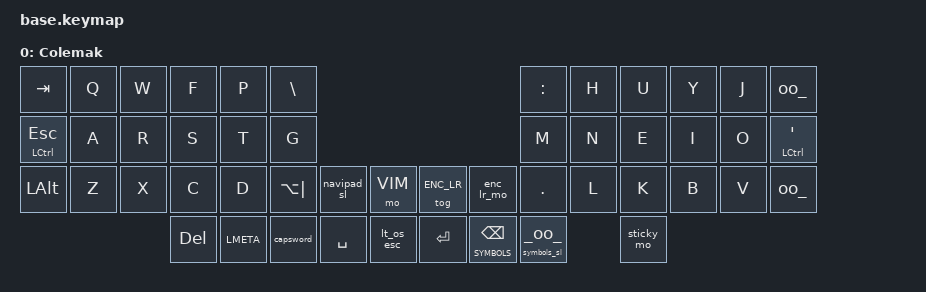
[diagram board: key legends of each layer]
/ {
    keymap {
        compatible = "zmk,keymap";
        colemak {
            label = "Colemak";
            sensor-bindings = <&inc_dec_kp DOWN UP>;
            // sensor-bindings = <&inc_dec_kp &rgb_inc &rgb_dec>;
            bindings = <
//                ┌───────────┬────┬────┬──────┬───────┬──────────┐                                                                ┌────────────┬──────┬───────────┬────┬────┬───────────┐
//                │    TAB    │  Q │  W │   F  │   P   │     \    │                                                                │      :     │   H  │     U     │  Y │  J │   _oo_    │
//                ├───────────┼────┼────┼──────┼───────┼──────────┤                                                                ├────────────┼──────┼───────────┼────┼────┼───────────┤
//                │  CTRL ESC │  A │  R │   S  │   T   │     G    │                                                                │      M     │   N  │     E     │  I │  O │  CTRL ' " │
//                ├───────────┼────┼────┼──────┼───────┼──────────┼────────────┬───────────┐   ┌────────────┬──────────────────────┼────────────┼──────┼───────────┼────┼────┼───────────┤
//                │    ALT    │  Z │  X │   C  │   D   │  LA( | ) │ navipad_sl │  mo VIM   │   │ tog ENC_LR │      enc_lr_mo       │      .     │   L  │     K     │  B │  V │   _oo_    │
//                └───────────┴────┴────┼──────┼───────┼──────────┼────────────┼───────────┤   ├────────────┼──────────────────────┼────────────┼──────┼───────────┼────┴────┴───────────┘
//                                      │  DEL │  META │ capsword │    SPACE   │ lt_os_esc │   │    enter   │ lt SYMBOLS BACKSPACE │ symbols_sl │ _oo_ │ sticky_mo │                      
//                                      └──────┴───────┴──────────┴────────────┴───────────┘   └────────────┴──────────────────────┴────────────┴──────┴───────────┘                      
              &kp TAB         &kp Q   &kp W   &kp F     &kp P       &kp BSLH                                                                            &kp COLON     &kp H   &kp U        &kp Y   &kp J   _oo_                  
              &mt LCTRL ESC   &kp A   &kp R   &kp S     &kp T       &kp G                                                                               &kp M         &kp N   &kp E        &kp I   &kp O   &mt LCTRL SINGLE_QUOTE
              &kp LALT        &kp Z   &kp X   &kp C     &kp D       &kp LA(PIPE)   &navipad_sl   &mo VIM          &tog ENC_LR   &enc_lr_mo              &kp DOT       &kp L   &kp K        &kp B   &kp V   _oo_                  
                                              &kp DEL   &kp LMETA   &capsword      &kp SPACE     &lt_os_esc       &kp RET       &lt SYMBOLS BACKSPACE   &symbols_sl   _oo_    &sticky_mo                                         
            >;
        };
	};
    conditional_layers {
        compatible = "zmk,conditional-layers";
        tri_layer {
            // &media_fn_mo
            if-layers = <OS VIM>;
            then-layer = <MEDIA_FN>;
            // if-layers = <OS MEDIA_FN>;
            // then-layer = <FN_KEYS>;
        };
    };
    behaviors {
        capsword: capsword {
            // tap - sticky / hold - momentary / double tap - toggle
			compatible = "zmk,behavior-tap-dance";
			label = "capsword";
			#binding-cells = <0>;
            tapping-term-ms = <150>;
			bindings = <&shift_color>, <&caps_word>;
		};
        navipad: navipad {
            // tap - sticky / hold - momentary / double tap - toggle
			compatible = "zmk,behavior-tap-dance";
			label = "navipad";
			#binding-cells = <0>;
			bindings = <&sl NAVIPAD>, <&tog NAVIPAD>;
		};
        mo_tog: behavior_mo_tog {
			compatible = "zmk,behavior-hold-tap";
			label = "mo_tog";
			#binding-cells = <2>;
			flavor = "hold-preferred";
			tapping-term-ms = <200>;
			bindings = <&mo>, <&tog>;
		};
		under_equal: under_equal {
			compatible = "zmk,behavior-mod-morph";
			label = "under_equal";
			bindings = <&kp UNDERSCORE>, <&kp EQUAL>;
			#binding-cells = <0>;
			mods = <(MOD_LSFT | MOD_RSFT)>;
		};
		minus_plus: minus_plus {
			compatible = "zmk,behavior-mod-morph";
			label = "minus_plus";
			bindings = <&kp MINUS>, <&kp PLUS>;
			#binding-cells = <0>;
			mods = <(MOD_LSFT | MOD_RSFT)>;
		};
        colon_semi: colon_semi {
			compatible = "zmk,behavior-mod-morph";
			label = "colon_semi";
			bindings = <&kp COLON>, <&kp SEMI>;
			#binding-cells = <0>;
			mods = <(MOD_LSFT|MOD_RSFT)>;
		};
        bspc_del: bspc_del {
			compatible = "zmk,behavior-mod-morph";
			label = "BSPC_DEL";
			bindings =
				<&kp BACKSPACE>,
				<&kp DELETE>;
			#binding-cells = <0>;
			mods = <(MOD_LALT|MOD_RALT)>;
		};
    };
};
